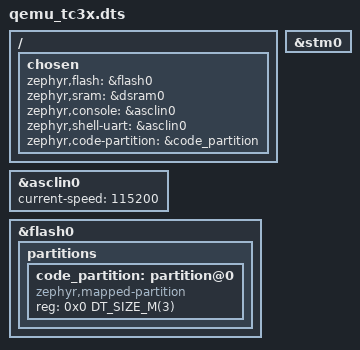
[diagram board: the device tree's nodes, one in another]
/*
 * SPDX-FileCopyrightText: Copyright (c) 2024 Infineon Technologies AG,
 * SPDX-FileCopyrightText: or an affiliate of Infineon Technologies AG. All rights reserved.
 * SPDX-FileCopyrightText: Copyright (c) 2026 Linumiz
 *
 * SPDX-License-Identifier: Apache-2.0
 */

/dts-v1/;

#include <qemu/tc3x.dtsi>

/ {
	chosen {
		zephyr,flash = &flash0;
		zephyr,sram = &dsram0;
		zephyr,console = &asclin0;
		zephyr,shell-uart = &asclin0;
		zephyr,code-partition = &code_partition;
	};
};

&asclin0 {
	current-speed = <115200>;
	status = "okay";
};

&stm0 {
	status = "okay";
};

&flash0 {
	partitions {
		#address-cells = <1>;
		#size-cells = <1>;
		ranges;

		code_partition: partition@0 {
			compatible = "zephyr,mapped-partition";
			reg = <0x0 DT_SIZE_M(3)>;
		};
	};
};
